# PIC32CX1025MTSH128 register map
Vendor: Microchip Technology; Series: PIC32CXMTSH; File version: 0
CPU: CM4 r0p1, selectable endian, MPU, FPU, 4 interrupt priority bits
Registers are 32-bit, read-write, reset 0x0 unless marked. A register's access mark holds for its fields unless they carry their own. Offsets are from the block's base; [hi:lo] are bit positions.

## SYSCWP — External Interrupt Controller
Base 0x400531A0; register names take the prefix SYSCWP_
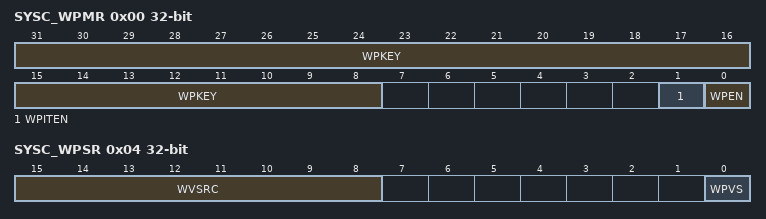
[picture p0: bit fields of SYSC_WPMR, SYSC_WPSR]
0x00 SYSC_WPMR — Write Protection Mode Register
  [31:8] WPKEY — Write Protection Key
    0x535943=PASSWD (Writing any other value in this field aborts the write operation of the WPEN and WPITEN bits. Always reads as 0.)
  [1] WPITEN — Write Protection Interrupt Enable
  [0] WPEN — Write Protection Enable
0x04 SYSC_WPSR ro — Write Protection Status Register
  [15:8] WVSRC — Write Violation Source
  [0] WPVS — Write Protection Register Violation Status

## TRNG — True Random Number Generator
Base 0x4400C000; register names take the prefix TRNG_
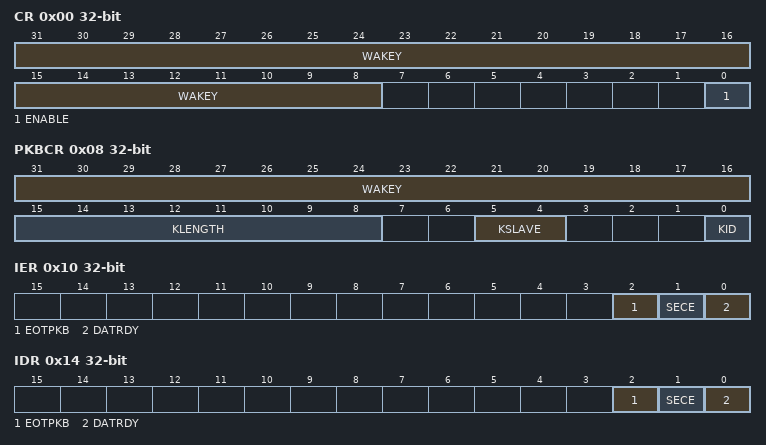
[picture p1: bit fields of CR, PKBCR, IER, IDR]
0x00 CR wo — Control Register
  [31:8] WAKEY — Register Write Access Key
    0x524E47=PASSWD (Writing any other value in this field aborts the write operation.)
  [0] ENABLE — Enable TRNG to Provide Random Values
0x04 MR — Mode Register
  [0] HALFR — Half Rate Enable
    0=DISABLED (Maximum stream rate provided (1 sample every 84 MCK clock cycles).); 1=ENABLED (Half maximum stream rate provided if the peripheral clock frequency is above 100 MHz (1 sample every 168 MCK clock cycles).)
0x08 PKBCR wo — Private Key Bus Control Register
  [31:16] WAKEY — Register Write Access Key
    0x524B=PASSWD (Writing any other value in this field aborts the write operation.)
  [15:8] KLENGTH — Key Length
  [5:4] KSLAVE — Key Bus Client
    0=AES_ID; 1=AESB_ID
  [0] KID — Key ID (Must be Always Written to 0)
0x10 IER wo — Interrupt Enable Register
  [2] EOTPKB — End Of Transfer on Private Key Bus Interrupt Enable
  [1] SECE — Security and/or Safety Event Interrupt Enable
  [0] DATRDY — Data Ready Interrupt Enable
0x14 IDR wo — Interrupt Disable Register
  [2] EOTPKB — End Of Transfer on Private Key Bus Interrupt Disable
  [1] SECE — Security and/or Safety Event Interrupt Disable
  [0] DATRDY — Data Ready Interrupt Disable
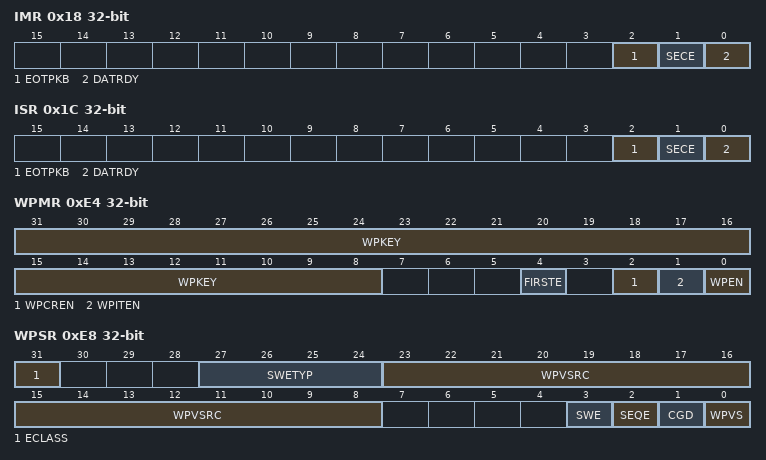
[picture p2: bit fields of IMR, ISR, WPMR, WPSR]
0x18 IMR ro — Interrupt Mask Register
  [2] EOTPKB — End Of Transfer on Private Key Bus Interrupt Mask
  [1] SECE — Security and/or Safety Event Interrupt Mask
  [0] DATRDY — Data Ready Interrupt Mask
0x1C ISR ro — Interrupt Status Register
  [2] EOTPKB — End Of Transfer on Private Key Bus (cleared on read)
  [1] SECE — Security and/or Safety Event (cleared on read)
  [0] DATRDY — Data Ready (cleared on read)
0x50 ODATA ro — Output Data Register
  [31:0] ODATA — Output Data
0xE4 WPMR — Write Protection Mode Register
  [31:8] WPKEY — Write Protection Key
    0x524E47=PASSWD (Writing any other value in this field aborts the write operation of bits WPEN, WPITEN and WPCREN. Always reads as 0.)
  [4] FIRSTE — First Error Report Enable
  [2] WPCREN — Write Protection Control Enable
  [1] WPITEN — Write Protection Interrupt Enable
  [0] WPEN — Write Protection Enable
0xE8 WPSR ro — Write Protection Status Register
  [31] ECLASS — Software Error Class (cleared on read)
    0=WARNING (An abnormal access that does not affect system functionality.); 1=ERROR (Reading TRNG_ODATA when TRNG was disabled or TRNG used for private key bus transfer. TRNG does not provide a random value. Writing to TRNG_PKBCR while a private key bus transfer is ongoing does not launch a new private key bus transfer.)
  [27:24] SWETYP — Software Error Type (cleared on read)
    0=READ_WO (TRNG is enabled and a write-only register has been read (Warning).); 1=WRITE_RO (TRNG is enabled and a write access has been performed on a read-only register (Warning).); 2=UNDEF_RW (Access to an undefined address.); 3=TRNG_DIS (The TRNG_ODATA register was read when TRNG was disabled or TRNG used for private key bus transfer (Error).); 4=PKB_BUSY (A write access to TRNG_PKBCR has been attempted during a private key bus transfer (Error).)
  [23:8] WPVSRC — Write Protection Violation Source (cleared on read)
  [3] SWE — Software Control Error (cleared on read)
  [2] SEQE — Internal Sequencer Error (cleared on read)
  [1] CGD — Clock Glitch Detected (cleared on read)
  [0] WPVS — Write Protection Violation Status (cleared on read)
